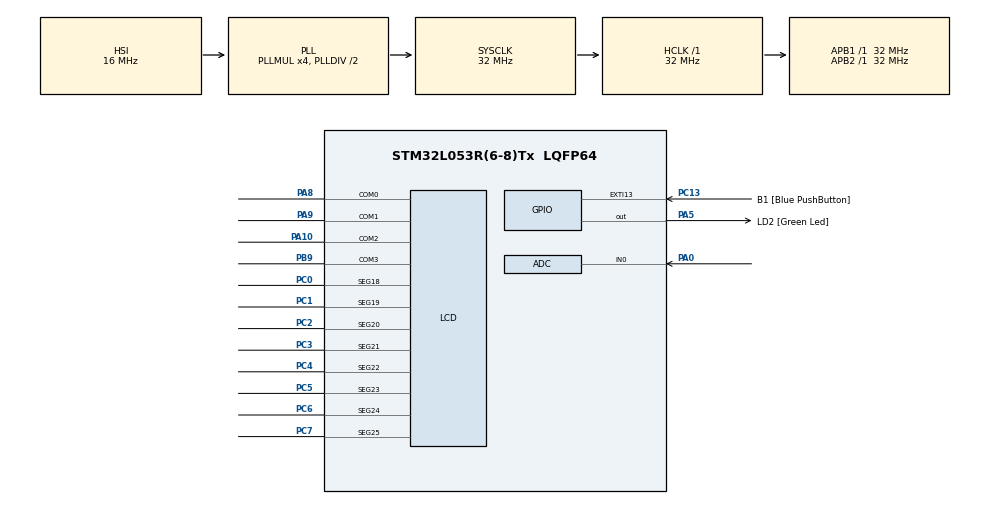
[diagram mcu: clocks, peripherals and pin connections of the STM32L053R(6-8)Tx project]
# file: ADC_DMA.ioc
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ADC.ClockPrescaler=ADC_CLOCK_ASYNC_DIV32
ADC.ContinuousConvMode=ENABLE
ADC.DMAContinuousRequests=ENABLE
ADC.SamplingTime=ADC_SAMPLETIME_12CYCLES_5
Dma.ADC.0.Direction=DMA_PERIPH_TO_MEMORY
Dma.ADC.0.Instance=DMA1_Channel1
Dma.ADC.0.MemDataAlignment=DMA_MDATAALIGN_WORD
Dma.ADC.0.MemInc=DMA_MINC_ENABLE
Dma.ADC.0.Mode=DMA_CIRCULAR
Dma.ADC.0.PeriphDataAlignment=DMA_PDATAALIGN_WORD
Dma.ADC.0.PeriphInc=DMA_PINC_DISABLE
Dma.ADC.0.Priority=DMA_PRIORITY_LOW
Dma.Request0=ADC
LCD.BlinkFrequency=LCD_BLINKFREQUENCY_DIV1024
LCD.Contrast=LCD_CONTRASTLEVEL_5
Mcu.Family=STM32L0
Mcu.Name=STM32L053R(6-8)Tx
Mcu.Package=LQFP64
NVIC.DMA1_Channel1_IRQn=true\:0\:0\:false\:false\:true\:false
PA0.Mode=IN0
PA0.Signal=ADC_IN0
PA10.Mode=1/4 Duty Cycle
PA10.Signal=LCD_COM2
PA13.GPIO_Label=TMS
PA13.Signal=SYS_SWDIO
PA14.GPIO_Label=TCK
PA14.Signal=SYS_SWCLK
PA2.GPIO_Label=USART_TX
PA2.Signal=USART2_TX
PA3.GPIO_Label=USART_RX
PA3.Signal=USART2_RX
PA5.GPIO_Label=LD2 [Green Led]
PA5.Signal=GPIO_Output
PA8.Mode=1/4 Duty Cycle
PA8.Signal=LCD_COM0
PA9.Mode=1/4 Duty Cycle
PA9.Signal=LCD_COM1
PB9.Mode=1/4 Duty Cycle
PB9.Signal=LCD_COM3
PC0.Mode=SEG18
PC0.Signal=LCD_SEG18
PC1.Mode=SEG19
PC1.Signal=LCD_SEG19
PC13.GPIO_Label=B1 [Blue PushButton]
PC13.GPIO_ModeDefaultEXTI=GPIO_MODE_IT_FALLING
PC13.Signal=GPXTI13
PC14-OSC32_IN.Mode=LSE-External-Oscillator
PC14-OSC32_IN.Signal=RCC_OSC32_IN
PC15-OSC32_OUT.Mode=LSE-External-Oscillator
PC15-OSC32_OUT.Signal=RCC_OSC32_OUT
PC2.Mode=SEG20
PC2.Signal=LCD_SEG20
PC3.Mode=SEG21
PC3.Signal=LCD_SEG21
PC4.Mode=SEG22
PC4.Signal=LCD_SEG22
PC5.Mode=SEG23
PC5.Signal=LCD_SEG23
PC6.Mode=SEG24
PC6.Signal=LCD_SEG24
PC7.Mode=SEG25
PC7.Signal=LCD_SEG25
PH0-OSC_IN.Signal=RCC_OSC_IN
PH1-OSC_OUT.Signal=RCC_OSC_OUT
ProjectManager.HeapSize=0x200
ProjectManager.StackSize=0x400
ProjectManager.TargetToolchain=MDK-ARM V5
RCC.AHBFreq_Value=32000000
RCC.APB1Freq_Value=32000000
RCC.APB1TimFreq_Value=32000000
RCC.APB2Freq_Value=32000000
RCC.APB2TimFreq_Value=32000000
RCC.HCLKFreq_Value=32000000
RCC.HSE_VALUE=8000000
RCC.HSI16_VALUE=16000000
RCC.HSI48_VALUE=48000000
RCC.HSI_VALUE=16000000
RCC.MSI_VALUE=2097000
RCC.PLLMUL=RCC_PLLMUL_4
RCC.RTCClockSelection=RCC_RTCCLKSOURCE_LSE
RCC.SYSCLKFreq_VALUE=32000000
RCC.SYSCLKSource=RCC_SYSCLKSOURCE_PLLCLK
RCC.VCOOutputFreq_Value=64000000
VP_ADC_Vref_Input.Mode=IN-Vrefint
VP_LCD_LCD_Bias.Mode=1/3 Bias
board=NUCLEO-L053R8

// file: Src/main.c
/**
  ******************************************************************************
  * File Name          : main.c
  * Description        : Main program body
  ******************************************************************************
  ** This notice applies to any and all portions of this file
  * that are not between comment pairs USER CODE BEGIN and
  * USER CODE END. Other portions of this file, whether
  * inserted by the user or by software development tools
  * are owned by their respective copyright owners.
  *
  * COPYRIGHT(c) 2017 STMicroelectronics
  *
  * Redistribution and use in source and binary forms, with or without modification,
  * are permitted provided that the following conditions are met:
  *   1. Redistributions of source code must retain the above copyright notice,
  *      this list of conditions and the following disclaimer.
  *   2. Redistributions in binary form must reproduce the above copyright notice,
  *      this list of conditions and the following disclaimer in the documentation
  *      and/or other materials provided with the distribution.
  *   3. Neither the name of STMicroelectronics nor the names of its contributors
  *      may be used to endorse or promote products derived from this software
  *      without specific prior written permission.
  *
  * THIS SOFTWARE IS PROVIDED BY THE COPYRIGHT HOLDERS AND CONTRIBUTORS "AS IS"
  * AND ANY EXPRESS OR IMPLIED WARRANTIES, INCLUDING, BUT NOT LIMITED TO, THE
  * IMPLIED WARRANTIES OF MERCHANTABILITY AND FITNESS FOR A PARTICULAR PURPOSE ARE
  * DISCLAIMED. IN NO EVENT SHALL THE COPYRIGHT HOLDER OR CONTRIBUTORS BE LIABLE
  * FOR ANY DIRECT, INDIRECT, INCIDENTAL, SPECIAL, EXEMPLARY, OR CONSEQUENTIAL
  * DAMAGES (INCLUDING, BUT NOT LIMITED TO, PROCUREMENT OF SUBSTITUTE GOODS OR
  * SERVICES; LOSS OF USE, DATA, OR PROFITS; OR BUSINESS INTERRUPTION) HOWEVER
  * CAUSED AND ON ANY THEORY OF LIABILITY, WHETHER IN CONTRACT, STRICT LIABILITY,
  * OR TORT (INCLUDING NEGLIGENCE OR OTHERWISE) ARISING IN ANY WAY OUT OF THE USE
  * OF THIS SOFTWARE, EVEN IF ADVISED OF THE POSSIBILITY OF SUCH DAMAGE.
  *
  ******************************************************************************
  */
#include "main.h"
#include "stm32l0xx_hal.h"
#include "adc.h"
#include "dma.h"
#include "lcd.h"
#include "gpio.h"

__IO uint16_t ADC_ConvertedValue[] = {0, 0, 0, 0};
/* USER CODE BEGIN PV */
/* Private variables ---------------------------------------------------------*/

/* USER CODE END PV */

void SystemClock_Config(void);

/* USER CODE BEGIN PFP */
/* Private function prototypes -----------------------------------------------*/

/* USER CODE END PFP */

int main(void)
{

  /* MCU Configuration----------------------------------------------------------*/

  /* Reset of all peripherals, Initializes the Flash interface and the Systick. */
  HAL_Init();

  /* Configure the system clock */
  SystemClock_Config();

  /* Initialize all configured peripherals */
	MX_DMA_Init();
	MX_GPIO_Init();
	MX_LCD_Init();
	LCD_GLASS_Clear();
	MX_ADC_Init();
	HAL_ADCEx_Calibration_Start(&hadc, ADC_SINGLE_ENDED);
  /* USER CODE BEGIN 2 */
	HAL_ADC_Start_DMA(&hadc, (uint32_t*)&ADC_ConvertedValue, 1);
  /* USER CODE END 2 */

  /* Infinite loop */
  while (1)
  {
	LCD_GLASS_Heartbeat(((float)ADC_ConvertedValue[0] / 4096) * 3.220);
  }

}

void HAL_ADC_ConvCpltCallback(ADC_HandleTypeDef* hadc)
{
    for(int i = 0; i < 4; i++)
    {
        ADC_ConvertedValue[i] = ADC_ConvertedValue[i] & 0xfff;
    }
}

/** System Clock Configuration
*/
void SystemClock_Config(void)
{

  RCC_OscInitTypeDef RCC_OscInitStruct;
  RCC_ClkInitTypeDef RCC_ClkInitStruct;
  RCC_PeriphCLKInitTypeDef PeriphClkInit;

    /**Configure the main internal regulator output voltage
    */
  __HAL_PWR_VOLTAGESCALING_CONFIG(PWR_REGULATOR_VOLTAGE_SCALE1);

    /**Configure LSE Drive Capability
    */
  __HAL_RCC_LSEDRIVE_CONFIG(RCC_LSEDRIVE_LOW);

    /**Initializes the CPU, AHB and APB busses clocks
    */
  RCC_OscInitStruct.OscillatorType = RCC_OSCILLATORTYPE_HSI|RCC_OSCILLATORTYPE_LSE;
  RCC_OscInitStruct.LSEState = RCC_LSE_ON;
  RCC_OscInitStruct.HSIState = RCC_HSI_ON;
  RCC_OscInitStruct.HSICalibrationValue = 16;
  RCC_OscInitStruct.PLL.PLLState = RCC_PLL_ON;
  RCC_OscInitStruct.PLL.PLLSource = RCC_PLLSOURCE_HSI;
  RCC_OscInitStruct.PLL.PLLMUL = RCC_PLLMUL_4;
  RCC_OscInitStruct.PLL.PLLDIV = RCC_PLLDIV_2;
  if (HAL_RCC_OscConfig(&RCC_OscInitStruct) != HAL_OK)
  {
    _Error_Handler(__FILE__, __LINE__);
  }

    /**Initializes the CPU, AHB and APB busses clocks
    */
  RCC_ClkInitStruct.ClockType = RCC_CLOCKTYPE_HCLK|RCC_CLOCKTYPE_SYSCLK
                              |RCC_CLOCKTYPE_PCLK1|RCC_CLOCKTYPE_PCLK2;
  RCC_ClkInitStruct.SYSCLKSource = RCC_SYSCLKSOURCE_PLLCLK;
  RCC_ClkInitStruct.AHBCLKDivider = RCC_SYSCLK_DIV1;
  RCC_ClkInitStruct.APB1CLKDivider = RCC_HCLK_DIV1;
  RCC_ClkInitStruct.APB2CLKDivider = RCC_HCLK_DIV1;

  if (HAL_RCC_ClockConfig(&RCC_ClkInitStruct, FLASH_LATENCY_1) != HAL_OK)
  {
    _Error_Handler(__FILE__, __LINE__);
  }

  PeriphClkInit.PeriphClockSelection = RCC_PERIPHCLK_RTC;
  PeriphClkInit.RTCClockSelection = RCC_RTCCLKSOURCE_LSE;
  if (HAL_RCCEx_PeriphCLKConfig(&PeriphClkInit) != HAL_OK)
  {
    _Error_Handler(__FILE__, __LINE__);
  }

    /**Configure the Systick interrupt time
    */
  HAL_SYSTICK_Config(HAL_RCC_GetHCLKFreq()/1000);

    /**Configure the Systick
    */
  HAL_SYSTICK_CLKSourceConfig(SYSTICK_CLKSOURCE_HCLK);

  /* SysTick_IRQn interrupt configuration */
  HAL_NVIC_SetPriority(SysTick_IRQn, 0, 0);
}

void _Error_Handler(char * file, int line)
{
  while(1)
  {
  }
}

/************************ (C) COPYRIGHT STMicroelectronics *****END OF FILE****/
